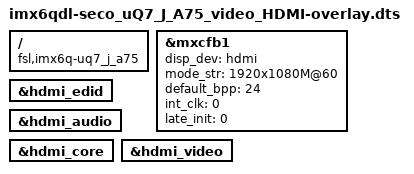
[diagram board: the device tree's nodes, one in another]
/dts-v1/;
/plugin/;

/ {
	compatible = "fsl,imx6q-uq7_j_a75", "fsl,imx6dl-uq7_j_a75", "fsl,imx6q", "fsl,imx6dl";

    fragment@0 {
   		target = <&mxcfb1>;
        __overlay__ {

            disp_dev    = "hdmi";
            status      = "okay";
            mode_str    = "1920x1080M@60";
		    default_bpp = <24>;
		    int_clk     = <0>;
		    late_init   = <0>;

		};
	};


    fragment@1 {
   		target = <&hdmi_edid>;
        __overlay__ {

            status      = "okay";

		};
	};


    fragment@2 {
   		target = <&hdmi_audio>;
        __overlay__ {

            status      = "okay";

		};
	};


    fragment@3 {
   		target = <&hdmi_core>;
        __overlay__ {

            status      = "okay";

		};
	};
	

    fragment@4 {
   		target = <&hdmi_video>;
        __overlay__ {

            status      = "okay";

		};
	};
};
